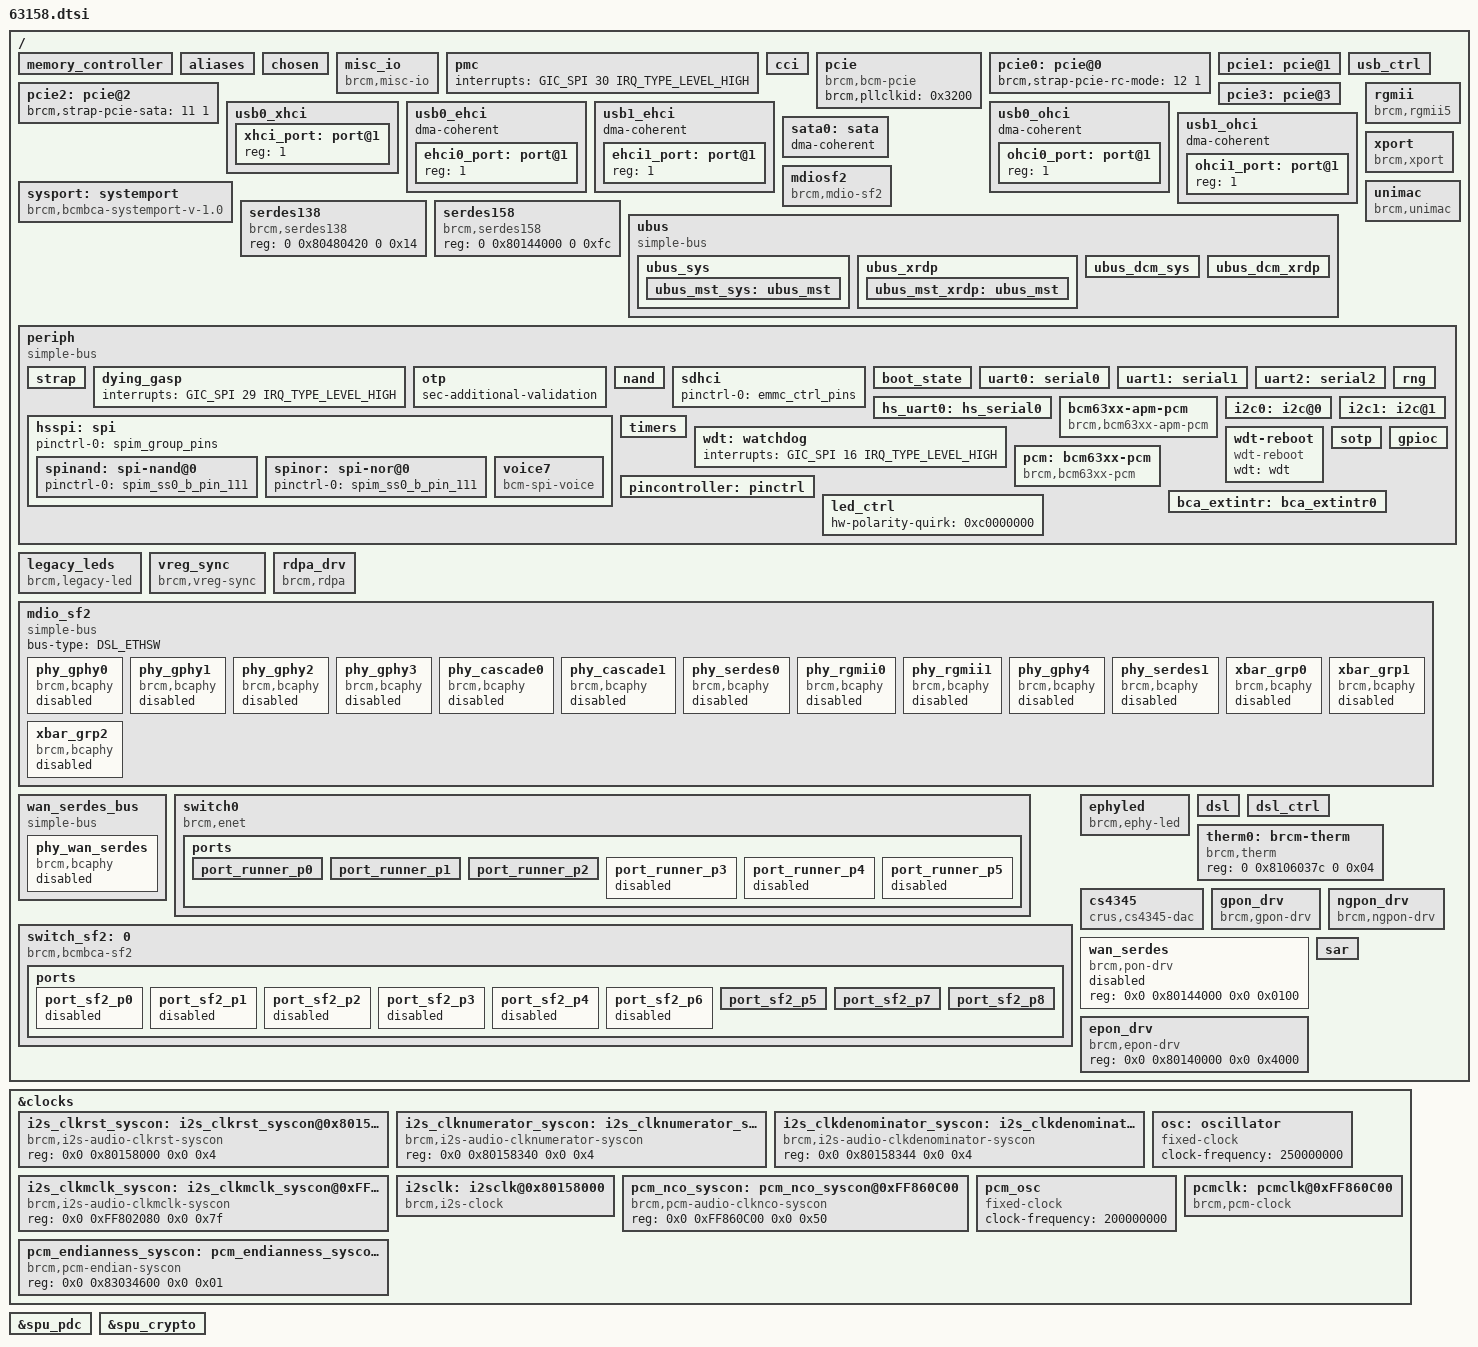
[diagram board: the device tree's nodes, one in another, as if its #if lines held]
/dts-v1/;

#include "linux_autoconf.h"

/* bootstrap reserved memory */
#include "../boot_rsvdmem.dtsi"

/ {
	/* arch */
	#define PMU_CORE0_SPI	9
	#define PMU_CORE1_SPI	10
	#define PMU_CORE2_SPI	11
	#define PMU_CORE3_SPI	12
	#include "../ip/bcm_b53_quad.dtsi"

	/* clocks */
	#define PERIPH_CLK		200000000
	#define HS_SPI_PLL_CLK	400000000
	#include "../ip/bcm_clocks.dtsi"

	/* broadcom memory reservations */
	#include "../bcm_rsvdmem.dtsi"

	/* memc */
	memory_controller {
		#define MEMC_REG_NAMES	"memc-int-clear-reg",	\
					"memc-int-mask-clear-reg",\
					"phyctl_idle_pad_ctl",	\
					"phyctl_idle_pad_en0",	\
					"phyctl_idle_pad_en1",	\
					"auto_self_refresh",	\
					"glb_gcfg"

		#define MEMC_REG	<0 0x80180E08 0 4>,	\
					<0 0x80180E14 0 4>,	\
					<0 0x801a0034 0 4>,	\
					<0 0x801a0038 0 4>,	\
					<0 0x801a003c 0 4>,	\
					<0 0x8018025c 0 4>,	\
					<0 0x80180004 0 4>

		#define MEMC_CPU_INT_LINE		18

		#include "../ip/memc.dtsi"
	};

	aliases {
		serial0 = &uart0;
		serial1 = &uart1;
		serial2 = &uart2;
		spi1 = &hsspi; /* 0 = legacy, 1 = high speed */
		spinand0 = &spinand;
		nand0 = &nand;
		spinor0 = &spinor;
		hs_serial0 = &hs_uart0;
	};

	chosen: chosen {
		stdout-path = "serial0:115200n8";
		/* increase coherent_pool size */
		bootargs = "coherent_pool=4M cpuidle_sysfs_switch pci=pcie_bus_safe console=ttyAMA0,115200 earlyprintk  rootwait rng_core.default_quality=1024";
	};

	misc_io {
		compatible = "brcm,misc-io";
		misc-periph-chip-id-rev = <0x0 0xff800000 0x0 0x4>;
		misc-periph-chip-id-mask = <0xfffff000>;
		misc-periph-chip-id-shift = <12>;
		misc-periph-chip-rev-mask = <0xfff>;
	};

	/* PMC */
	pmc: pmc {
		#define PMC_REG_OFFSET              0x0 0x80201000
		#define PMC_REG_SIZE                0x0 0x3800
		#define PROCMON_REG_OFFSET          0x0 0x80280000
		#define PROCMON_REG_SIZE            0x0 0x184
		#include "../ip/bcm_pmc_1_x.dtsi"
		interrupt-names = "pmc-irq";
		interrupts = <GIC_SPI 30 IRQ_TYPE_LEVEL_HIGH>;
	};

	cci: cci {
		#define CCI_OFFSET					0x0 0x81100000 
		#define CCI_SIZE					0x0 0x8000
		#define SLAVEINTF_CPU_NUM			1
		#include "../ip/bcm_arm_cci500.dtsi"
	};
	
#if defined(CONFIG_BCM_PCIE_HCD) || defined(CONFIG_BCM_PCIE_HCD_MODULE)
	/* pcie common */
	pcie: pcie {
		compatible = "brcm,bcm-pcie";
		device_type = "cpci";
#if (CONFIG_BRCM_CHIP_REV!=0x63158A0)
		/* port 0,1 share same clock */
		brcm,pllclkid = <0x3200>;
#else
		brcm,pllclkid = <0x3210>;
#endif
	};

	/* pcie core 0 */
	pcie0: pcie@0 {
		#define PCIE_ID				0
		#define PCIE_SPI			60
		#define PCIE_ADDR			0x80040000
		#define PCIE_SIZE			0x0000A000
		#define PCIE_RANGE_ADDR		0xC0000000
		#define PCIE_RANGE_SIZE		0x10000000
		#include "../ip/bcm_pcie_core.dtsi" 
		brcm,strap-pcie-rc-mode=<12 1>; 
	};

	/* pcie core 1 */
	pcie1: pcie@1 {
		#define PCIE_ID				1
		#define PCIE_SPI			61
		#define PCIE_ADDR			0x80050000
		#define PCIE_SIZE			0x0000A000
		#define PCIE_RANGE_ADDR		0xD0000000
		#define PCIE_RANGE_SIZE		0x10000000
		#include "../ip/bcm_pcie_core.dtsi"
	};

	/* pcie core 2 */
	pcie2: pcie@2 {
		#define PCIE_ID				2
		#define PCIE_SPI			62
		#define PCIE_ADDR			0x80060000
		#define PCIE_SIZE			0x0000A000
		#define PCIE_RANGE_ADDR		0xE0000000
		#define PCIE_RANGE_SIZE		0x10000000
		#include "../ip/bcm_pcie_core.dtsi"
		brcm,strap-pcie-sata=<11 1>;
	};

	/* pcie core 3 */
	pcie3: pcie@3 {
		#define PCIE_ID				3
		#define PCIE_SPI			63
		#define PCIE_ADDR			0x80070000
		#define PCIE_SIZE			0x0000B000
		#define PCIE_RANGE_ADDR		0xB0000000
		#define PCIE_RANGE_SIZE		0x10000000
		#include "../ip/bcm_pcie_core.dtsi"
	};
#endif /* defined(CONFIG_BCM_PCIE_HCD) || defined(CONFIG_BCM_PCIE_HCD_MODULE) */

#if (defined(CONFIG_BCM_PDC) || defined(CONFIG_BCM_PDC_MODULE)) && \
    (defined(CONFIG_BCM_SPU) || defined(CONFIG_BCM_SPU_MODULE))
	/* spu */
	#define SPU_DMA_ADDR			0x00000000 0x8001c000
	#define SPU_DMA_SIZE			0x00000000 0x448
	#define SPU_DMA_NUM_CHAN		4
	#define SPU_DMA_NUM_AE			1
	#define SPU_CRYPTO_ADDR			0x00000000 0x8001d000
	#define SPU_CRYPTO_SIZE			0x00000000 0x64
	#define SPU_GMAC_SPI			75
	#include "../ip/bcm_spu.dtsi"
#endif

	/* usb */
	usb_ctrl: usb_ctrl {
		#define USB_CTRL_ADDR		0x0 0x8000c200
		#define USB_CTRL_SIZE 		0x0 0x100
		#include "../ip/bcm_usb_ctrl.dtsi"
	};

	usb0_xhci: usb0_xhci {
		#define USB_ADDR 		0x0 0x8000d000
		#define USB_SIZE		0x0 0x1000
		#define USB_IRQ			123
		#include "../ip/bcm_usb_xhci.dtsi"

		xhci_port: port@1{
			reg = <1>;
			#trigger-source-cells = <0>;
		};
	};

	usb0_ehci: usb0_ehci {
		#define USB_ADDR		0x0 0x8000c300
		#define USB_SIZE		0x0 0x100
		#define USB_IRQ			125
		#include "../ip/bcm_usb_ehci.dtsi"

  		dma-coherent;

 		ehci0_port: port@1{
			reg = <1>;
			#trigger-source-cells = <0>;
		};
	};

	usb1_ehci: usb1_ehci {
		#define USB_ADDR		0x0 0x8000c500
		#define USB_SIZE		0x0 0x100
		#define USB_IRQ			122
		#include "../ip/bcm_usb_ehci.dtsi"

  		dma-coherent;

		ehci1_port: port@1{
			reg = <1>;
			#trigger-source-cells = <0>;
		};
	};

	usb0_ohci: usb0_ohci {
		#define USB_ADDR		0x0 0x8000c400
		#define USB_SIZE		0x0 0x100
		#define USB_IRQ			124
		#include "../ip/bcm_usb_ohci.dtsi"

  		dma-coherent;

 		ohci0_port: port@1{
			reg = <1>;
			#trigger-source-cells = <0>;
		};
	};

	usb1_ohci: usb1_ohci {
		#define USB_ADDR		0x0 0x8000c600
		#define USB_SIZE		0x0 0x100
		#define USB_IRQ			121
		#include "../ip/bcm_usb_ohci.dtsi"

  		dma-coherent;

 		ohci1_port: port@1{
			reg = <1>;
			#trigger-source-cells = <0>;
		};
	};

	sata0: sata {
		#define AHCI_ADDR		0x0 0x8000a000
		#define AHCI_SIZE		0x0 0x2c
		#define SATA_CTRL_ADDR	0x0 0x80008000
		#define SATA_CTRL_SIZE	0x0 0x2000
		#define AHCI_SS_ADDR	0x0 0x8000a100
		#define AHCI_SS_SIZE	0x0 0x80
		#define AHCI_IRQ		45
		#include "../ip/bcm_sata.dtsi"
#if defined(CONFIG_BCM_GLB_COHERENCY)		
		dma-coherent;
#endif
	};

	sysport: systemport {
		compatible = "brcm,bcmbca-systemport-v-1.0";
		qphy-avaiable=<0x01>;
		sphy-available=<0x01>;
		reg-names = "systemport-rbuf-base", "systemport-rdma-base",
				"systemport-tdma-base",
				"systemport-umac-base",
				"systemport-topctrl-base";
		reg =	<0x0 0x80490400 0x0 0x14>,
			<0x0 0x80492000 0x0 0x1060>,
			<0x0 0x80494000 0x0 0x650>,
			<0x0 0x80490800 0x0 0x650>,
			<0x0 0x80490000 0x0 0x10>;
		ethsw = <&switch_sf2>;
	};

	mdiosf2 {
		compatible = "brcm,mdio-sf2";
		reg = <0x0 0x804805c0 0x0 0x10>,
		      <0x0 0x80480000 0x0 0x4>;
	};

	rgmii: rgmii {
		compatible = "brcm,rgmii5";
		reg = <0x0 0x80480164 0x0 12>, <0x0 0xff85a000 0x0 4>, /* rgmii0 P12 crossbar external EP3 */
		      <0x0 0x80480158 0x0 12>, <0x0 0xff85a004 0x0 4>, /* rgmii1 P11 crossbar external EP2 */
		      <0x0 0x80480170 0x0 12>, <0x0 0xff85a008 0x0 4>; /* rgmii2 P13/SF2.P3 */
	};

	xport {
		compatible = "brcm,xport";
		reg = <0x0 0x80138000 0x0 0x331c>,  /* XPORT base */
		      <0x0 0x80147800 0x0 0x0800>;  /* XLIF base */
	};

	unimac {
		compatible = "brcm,unimac";
		reg = <0x0 0x82da0000 0x0 0x3000>,
			  <0x0 0x82da8000 0x0 0xc00>,
			  <0x0 0x82daa000 0x0 0xc00>;
		conf_offset = <0x1000>;
		mib_offset = <0x400>;
		top_offset = <0x400>;
	};

	serdes138 {
		compatible = "brcm,serdes138";
		reg = <0 0x80480420 0 0x14>;   /* SINGLE_SERDES */
	};

	serdes158 {
		compatible = "brcm,serdes158";
		reg = <0 0x80144000 0 0xfc>;   /* WAN_TOP */
	};

	/* UBUS */
	ubus: ubus {
		compatible = "simple-bus";
		#address-cells = <2>;
		#size-cells = <2>;
		ranges;

		ubus_sys: ubus_sys {
			#address-cells = <2>;
			#size-cells = <2>;
			#define UBUS_SYSTOP_OFFSET         0x0 0x83000000
			#define UBUS_SYSTOP_SIZE           0x0 0x80
			#define UBUS_REGISTRATION_OFFSET   0x0 0x83000200
			#define UBUS_REGISTRATION_SIZE     0x0 0x80
			#define UBUS_COHERENCY_PORT_OFFSET 0x0 0x810A0400
			#define UBUS_COHERENCY_PORT_SIZE   0x0 0x400
			#define UBUS_MODULE_XRDP           0x0
			#include "../ip/bcm_ubus4.dtsi"
			ubus_mst_sys: ubus_mst {
				reg-names = "BIU", "PER", "USB", "SPU",
					"DSL", "PERDMA", "PCIE0", "PCIE2",
					"PCIE3", "DSLCPU", "PMC", "SWH";
				reg = <0x0 0x83020000 0x0 0x1000>,
					<0x0 0x83034000 0x0 0x1000>,
					<0x0 0x83074000 0x0 0x1000>,
					<0x0 0x83050000 0x0 0x1000>,
					<0x0 0x8305C000 0x0 0x1000>,
					<0x0 0x8303C000 0x0 0x1000>,
					<0x0 0x8300C000 0x0 0x1000>,
					<0x0 0x83064000 0x0 0x1000>,
					<0x0 0x8306C000 0x0 0x1000>,
					<0x0 0x8301C000 0x0 0x1000>,
					<0x0 0x8302C000 0x0 0x1000>,
					<0x0 0x83048000 0x0 0x1000>;
			};
		};

		ubus_xrdp: ubus_xrdp {
			#address-cells = <2>;
			#size-cells = <2>;
			#define UBUS_SYSTOP_OFFSET        0x0 0x83400000
			#define UBUS_SYSTOP_SIZE          0x0 0x80
			#define UBUS_REGISTRATION_OFFSET  0x0 0x83400200
			#define UBUS_REGISTRATION_SIZE    0x0 0x80
			#define UBUS_MODULE_XRDP          0x1
			#include "../ip/bcm_ubus4.dtsi"
			ubus_mst_xrdp: ubus_mst {
				reg-names = "QM", "DQM", "DMA0", "NATC",
					"RQ0";
				reg = <0x0 0x834C4000 0x0 0x1000>,
					<0x0 0x834BC000 0x0 0x1000>,
					<0x0 0x8347C000 0x0 0x1000>,
					<0x0 0x834B8000 0x0 0x1000>,
					<0x0 0x83498000 0x0 0x1000>;
			};
		};

		ubus_dcm_sys: ubus_dcm_sys {
			#define UBUS_DCM_CLK_OFFSET  0x0 0x83000080
			#define UBUS_DCM_CLK_SIZE    0x0 0x80
			#define UBUS_MODULE_XRDP     0x0
			#include "../ip/bcm_ubus4_dcm.dtsi"
		};
		ubus_dcm_xrdp: ubus_dcm_xrdp {
			#define UBUS_DCM_CLK_OFFSET  0x0 0x83400080
			#define UBUS_DCM_CLK_SIZE    0x0 0x80
			#define UBUS_MODULE_XRDP     0x1
			#include "../ip/bcm_ubus4_dcm.dtsi"
		};
	};

	periph {
		compatible = "simple-bus";
		#address-cells = <2>;
		#size-cells = <2>;
		ranges = <0x0 0x0 0x0 0xff800000 0x0 0x62000>;

		strap: strap {
			#define STRAP_REG_OFFSET            0x0 0x2600
			#define STRAP_REG_SIZE              0x0 0x4
			#include "../ip/bcm_strap.dtsi"
			boot-select-0=<0 1>;
			boot-select-1=<1 1>;
			boot-select-2=<2 1>;
			boot-select-3=<3 1>;
			boot-select-4=<4 1>;
			boot-select-5=<5 1>;
			bootrom-boot=<7 0>;
			sata-strap-enable-bit=<11 0>;
		};

		dying_gasp: dying_gasp {
			#define DG_IRQ_MASK_REG_OFFSET	0x0 0x5A024
			#define DG_IRQ_MASK_REG_SIZE	0x0 0x4
			#define DG_UART_DR_OFFSET	0x0 0x12000
			#define DG_UART_DR_SIZE		0x0 0x4
			#include "../ip/bcm_dgasp_pmc.dtsi"
			interrupts = <GIC_SPI 29 IRQ_TYPE_LEVEL_HIGH>;
		};

		otp: otp {
			#define OTP_REG_OFFSET            0x0 0x2800 
			#define OTP_REG_SIZE              0x0 0x54
			#include "../ip/bcm_otp.dtsi"
			sec-additional-validation;
		};

		/* NAND controller */
		nand: nand {
			pinctrl-0 = <&nand_data_pins &nand_ctrl_pins &nand_ce_b_pin_48>;
			pinctrl-names = "default";
			#define NAND_CTRL_OFFSET		0x0 0x1800
			#define NAND_CTRL_SIZE			0x0 0x400
			#define NAND_INTR_OFFSET		0x0 0x2000
			#define NAND_INTR_SIZE			0x0 0x10
			#define NAND_CACHE_OFFSET		0x0 0x1C00
			#define NAND_CACHE_SIZE			0x0 0x200
			#include "../ip/bcm_nand7_1.dtsi"
		};

	   	/* EMMC */
		sdhci: sdhci {
			pinctrl-0 = <&emmc_ctrl_pins>;
			pinctrl-names="default";	
#if (CONFIG_BRCM_CHIP_REV!=0x63158A0)
			#define SDHCI_OFFSET			0x00000000 0x10000
			#define SDHCI_SIZE			0x00000000 0x100
			#define SDHCI_TOPCFG_OFFSET		0x00000000 0x10100
			#define SDHCI_TOPCFG_SIZE		0x00000000 0x100
			#define SDHCI_BOOT_OFFSET		0x00000000 0x10200
			#define SDHCI_BOOT_SIZE			0x00000000 0x40
			#define SDHCI_AHBSS_CTRL_OFFSET		0x00000000 0x10300
			#define SDHCI_AHBSS_CTRL_SIZE		0x00000000 0x100
#else
			#define SDHCI_OFFSET			0x00000000 0x58000
			#define SDHCI_SIZE			0x00000000 0x100
			#define SDHCI_TOPCFG_OFFSET		0x00000000 0x58100
			#define SDHCI_TOPCFG_SIZE		0x00000000 0x100
			#define SDHCI_BOOT_OFFSET		0x00000000 0x58200
			#define SDHCI_BOOT_SIZE			0x00000000 0x40
			#define SDHCI_AHBSS_CTRL_OFFSET		0x00000000 0x58300
			#define SDHCI_AHBSS_CTRL_SIZE		0x00000000 0x100
#endif				
			#define SDIO_EMMC_SPI			95
			#include "../ip/bcm_sdhci.dtsi"
		};
	
		/* boot state */
		boot_state: boot_state {
			#define RESET_REASON_OFFSET  0x0 0x2628
			#define RESET_REASON_SIZE    0x0 0x4
			#define RESET_STATUS_OFFSET  0x0 0x5a03c
			#define RESET_STATUS_SIZE    0x0 0x4
			#include "../ip/bcm_boot_state_v2.dtsi"
		};

		/* UART 1*/
		uart0: serial0 {
#if (CONFIG_BRCM_CHIP_REV!=0x63158A0)
			#define UART_OFFSET			0x0 0x12000
			#define UART_SIZE			0x0 0x1000
			#define UART_SPI			32
			#define UART_CLK_LABEL			refclk50mhz
			#define UART_CLK			50000000
			#include "../ip/bcm_arm_uart.dtsi"
#else
			#define UART_OFFSET			0x0 0x640
			#define UART_SIZE			0x0 0x18
			#define UART_SPI 			32
			#include "../ip/bcm_uart.dtsi"
#endif
		};

#if (CONFIG_BRCM_CHIP_REV!=0x63158A0)
		uart1: serial1 {
			#define UART_OFFSET			0x0 0x13000
			#define UART_SIZE			0x0 0x1000
			#define UART_SPI			33
			#define UART_CLK_LABEL			refclk50mhz
			#define UART_CLK			50000000
			#include "../ip/bcm_arm_uart.dtsi"
		};

		uart2: serial2 {
			#define UART_OFFSET			0x0 0x14000
			#define UART_SIZE			0x0 0x1000
			#define UART_SPI			35
			#define UART_CLK_LABEL			refclk50mhz
			#define UART_CLK			50000000
			#include "../ip/bcm_arm_uart.dtsi"
		};
#endif

		hs_uart0: hs_serial0 {
#if (CONFIG_BRCM_CHIP_REV!=0x63158A0)
			#define UART_OFFSET			0x0 0x10400
			#define UART_SIZE			0x0 0x1E0
#else			
			#define UART_OFFSET			0x0 0x58400
			#define UART_SIZE			0x0 0x1E0
#endif			
			#define UART_SPI 			34
			#include "../ip/bcm_hs_uart.dtsi"
		};

		/* HS SPI */
		hsspi: spi {
			pinctrl-0 = <&spim_group_pins>;
			pinctrl-names = "default";
			#define HS_SPI_OFFSET			0x0 0x1000
			#define HS_SPI_SIZE			0x0 0x600
			#define HS_SPI_MAX_FREQ			50000000
			/* #define HS_SPIM_SPI			37 */
			#include "../ip/bcm_hsspi.dtsi"
			spinand: spi-nand@0 {
				pinctrl-0 = <&spim_ss0_b_pin_111>;
				pinctrl-names = "default";
				#define SPINAND_MAX_FREQ	50000000
				#include "../ip/bcm_spinand.dtsi"
			};
			spinor: spi-nor@0 {
				pinctrl-0 = <&spim_ss0_b_pin_111>;
				pinctrl-names = "default";
				#define SPINOR_MAX_FREQ	50000000
				#include "../ip/bcm_spinor.dtsi"
			};
			voice7 {
				pinctrl-0 = <&pcm_sdin_pin_42 &pcm_sdout_pin_43 &pcm_clk_pin_44 &pcm_fs_pin_45>;
				pinctrl-names = "default";
				compatible = "bcm-spi-voice";
				reg = <7>; /* chip select 7 */
				spi-index = <7>;/* ZSI/ISI header position index */
				spi-max-frequency = <1024000>;
			};
		};

		bcm63xx-apm-pcm {
			compatible = "brcm,bcm63xx-apm-pcm";
			reg = <0x0 0x60000 0x0 0x1c60>;
			interrupts = <GIC_SPI 78 IRQ_TYPE_LEVEL_HIGH>;
		};		

		rng: rng {
			#define RNG200_OFFSET			0x0 0x00000b80
			#define RNG200_SIZE			0x0 0x28
			#include "../ip/bcm_rng200.dtsi"
		};

		i2c0: i2c@0 {
			#define I2C_OFFSET			0x0 0x2100
			#define I2C_SIZE			0x0 0x60
			#include "../ip/bcm_i2c_bus.dtsi"
		};

		/* use second i2c bus for pon sfp i2c device */
		i2c1: i2c@1 {
			#define I2C_OFFSET			0x0 0x5a800
			#define I2C_SIZE			0x0 0x60
			#include "../ip/bcm_i2c_bus.dtsi"
		};

		/* periph timers */
		timers: timers {
			#define TIMERS_OFFSET		0x0 0x400
			#define TIMERS__SIZE		0x0 0x48
			#define TIMER0_SPI			64
			#define TIMER1_SPI			65
			#define TIMER2_SPI			66
			#define TIMER3_SPI			67
			#include "../ip/bcm_timer.dtsi"
		};

		/* watchdog */
		wdt: watchdog {
			#define WATCHDOG_OFFSET			0x0 0x480
			#define WATCHDOG_SIZE			0x0 0x10
			#define WATCHDOG_TIMEOUT		80
			#include "../ip/bcm_wdt.dtsi"
			interrupts = <GIC_SPI 16 IRQ_TYPE_LEVEL_HIGH>;
		};

		/* watchdog reboot */
		wdt-reboot {
			compatible = "wdt-reboot";
			wdt = <&wdt>;
		};

		/* sotp */
		sotp {
			#define SOTP_OFFSET			0x0 0xc00
			#define SOTP_SIZE			0x0 0x84
			#include "../ip/bcm_sotp.dtsi"
		};
	
		pcm: bcm63xx-pcm {
			compatible = "brcm,bcm63xx-pcm";
			reg = <0x0 0x60C00 0x0 0x1060>;
			interrupts = <GIC_SPI 78 IRQ_TYPE_LEVEL_HIGH>,<GIC_SPI 79 IRQ_TYPE_LEVEL_HIGH>;
			clocks = <&pcmclk>, <&pcm_osc>;
			clock-names = "pcmclk","pcmosc"; 
		};		

		/* pinctrl */
		pincontroller: pinctrl {
			#define PINCTRL_OFFSET       0x0 0x554
			#define PINCTRL_SIZE         0x0 0xc
			#define PINCTRL_NUM_PINS     126
			#define PINCTRL_NUM_FUNC     8
			#define PINCTRL_GPIO_FUNC    5
			#include "../ip/bcm_bca_pinctrl.dtsi"
			#include "63158_pinctrl.dtsi"
		};
		/* gpio */
		gpioc: gpioc {
			#define GPIO_DIR_OFFSET      0x0 0x500
			#define GPIO_DIR_SIZE        0x0 0x20
			#define GPIO_DATA_OFFSET     0x0 0x520
			#define GPIO_DATA_SIZE       0x0 0x20
			#define NUM_OF_GPIOS         126
			#include "../ip/bcm_bca_gpio.dtsi"
		};

		/* external interrups */
		bca_extintr: bca_extintr0 {
			#define EXTINTR_OFFSET       0x0 0x4
			#define EXTINTR_SIZE         0x0 0x48
			#define MAX_EXT_INTR         8
			#include "../ip/bcm_bca_extintr.dtsi"
			external_interrupts = <176 177 178 179 180 181 182 183>;
		};

		/* Led Controller */
		led_ctrl: led_ctrl {
			#define LED_GLBL_CTRL_OFFSET     0 0x800
			#define LED_GLBL_CTRL_SIZE       0 0x4 
			#define LED_HW_EN_OFFSET         0 0x808
			#define LED_HW_EN_SIZE           0 0x4
			#define LED_SER_SHIFT_OFFSET     0 0x80c
			#define LED_SER_SHIFT_SIZE       0 0x4
			#define LED_FLASH_RATE_OFFSET    0 0x810
			#define LED_FLASH_RATE_SIZE      0 0x10
			#define LED_BRIGHTNESS_OFFSET    0 0x820
			#define LED_BRIGHTNESS_SIZE      0 0x10
			#define LED_POWER_LED_CFG_OFFSET 0 0x830
			#define LED_POWER_LED_CFG_SIZE   0 0x4
			#define LED_POWER_LUT_OFFSET     0 0x834
			#define LED_POWER_LUT_SIZE       0 0x80
			#define LED_HW_POLARITY_OFFSET   0 0x8b4
			#define LED_HW_POLARITY_SIZE     0 0x4
			#define LED_SW_DATA_OFFSET       0 0x8b8
			#define LED_SW_DATA_SIZE         0 0x4
			#define LED_SW_POLARITY_OFFSET   0 0x8bc
			#define LED_SW_POLARITY_SIZE     0 0x4
			#define LED_PAR_POLARITY_OFFSET  0 0x8c0
			#define LED_PAR_POLARITY_SIZE    0 0x4
			#define LED_SER_POLARITY_OFFSET  0 0x8c4
			#define LED_SER_POLARITY_SIZE    0 0x4
			#define LED_MASK_OFFSET          0 0x804 /*????*/
			#define LED_MASK_SIZE            0 0x4
			#define MAX_SUPPORTED_LEDS       32

			status = "okay";
			hw-polarity-quirk = <0xc0000000>;
			#include "../ip/bcm_led_ctrl.dtsi"
			#include "63158_leds.dtsi"
		};
	};

	legacy_leds: legacy_leds {
		compatible = "brcm,legacy-led";
	};

	vreg_sync: vreg_sync {
		compatible = "brcm,vreg-sync";
	};

	/* xrdp,wan_bbh,xlif */
	rdpa_drv {
		compatible = "brcm,rdpa";
		reg = <0x0 0x82000000 0x0 0xE51000>, 
			<0x0 0x80170000 0x0 0x9000>, 
			<0x0 0x80147800 0x0 0x800>;
                interrupts = <GIC_SPI 106 IRQ_TYPE_LEVEL_HIGH>, /* INTERRUPT_XRDP_FPM */
                             <GIC_SPI 128 IRQ_TYPE_LEVEL_HIGH>, /* INTERRUPT_XRDP_QUEUE_0 */
                             <GIC_SPI 129 IRQ_TYPE_LEVEL_HIGH>, /* INTERRUPT_XRDP_QUEUE_1 */
                             <GIC_SPI 130 IRQ_TYPE_LEVEL_HIGH>, /* INTERRUPT_XRDP_QUEUE_2 */
                             <GIC_SPI 131 IRQ_TYPE_LEVEL_HIGH>, /* INTERRUPT_XRDP_QUEUE_3 */
                             <GIC_SPI 132 IRQ_TYPE_LEVEL_HIGH>, /* INTERRUPT_XRDP_QUEUE_4 */
                             <GIC_SPI 133 IRQ_TYPE_LEVEL_HIGH>, /* INTERRUPT_XRDP_QUEUE_5 */
                             <GIC_SPI 134 IRQ_TYPE_LEVEL_HIGH>, /* INTERRUPT_XRDP_QUEUE_6 */
                             <GIC_SPI 135 IRQ_TYPE_LEVEL_HIGH>, /* INTERRUPT_XRDP_QUEUE_7 */
                             <GIC_SPI 136 IRQ_TYPE_LEVEL_HIGH>, /* INTERRUPT_XRDP_QUEUE_8 */
                             <GIC_SPI 137 IRQ_TYPE_LEVEL_HIGH>, /* INTERRUPT_XRDP_QUEUE_9 */
                             <GIC_SPI 138 IRQ_TYPE_LEVEL_HIGH>, /* INTERRUPT_XRDP_QUEUE_10 */
                             <GIC_SPI 139 IRQ_TYPE_LEVEL_HIGH>, /* INTERRUPT_XRDP_QUEUE_11 */
                             <GIC_SPI 140 IRQ_TYPE_LEVEL_HIGH>, /* INTERRUPT_XRDP_QUEUE_12 */
                             <GIC_SPI 141 IRQ_TYPE_LEVEL_HIGH>, /* INTERRUPT_XRDP_QUEUE_13 */
                             <GIC_SPI 142 IRQ_TYPE_LEVEL_HIGH>, /* INTERRUPT_XRDP_QUEUE_14 */
                             <GIC_SPI 143 IRQ_TYPE_LEVEL_HIGH>, /* INTERRUPT_XRDP_QUEUE_15 */
                             <GIC_SPI 144 IRQ_TYPE_LEVEL_HIGH>, /* INTERRUPT_XRDP_QUEUE_16 */
                             <GIC_SPI 145 IRQ_TYPE_LEVEL_HIGH>, /* INTERRUPT_XRDP_QUEUE_17 */
                             <GIC_SPI 146 IRQ_TYPE_LEVEL_HIGH>, /* INTERRUPT_XRDP_QUEUE_18 */
                             <GIC_SPI 147 IRQ_TYPE_LEVEL_HIGH>, /* INTERRUPT_XRDP_QUEUE_19 */
                             <GIC_SPI 148 IRQ_TYPE_LEVEL_HIGH>, /* INTERRUPT_XRDP_QUEUE_20 */
                             <GIC_SPI 149 IRQ_TYPE_LEVEL_HIGH>, /* INTERRUPT_XRDP_QUEUE_21 */
                             <GIC_SPI 150 IRQ_TYPE_LEVEL_HIGH>, /* INTERRUPT_XRDP_QUEUE_22 */
                             <GIC_SPI 151 IRQ_TYPE_LEVEL_HIGH>, /* INTERRUPT_XRDP_QUEUE_23 */
                             <GIC_SPI 152 IRQ_TYPE_LEVEL_HIGH>, /* INTERRUPT_XRDP_QUEUE_24 */
                             <GIC_SPI 153 IRQ_TYPE_LEVEL_HIGH>, /* INTERRUPT_XRDP_QUEUE_25 */
                             <GIC_SPI 154 IRQ_TYPE_LEVEL_HIGH>, /* INTERRUPT_XRDP_QUEUE_26 */
                             <GIC_SPI 155 IRQ_TYPE_LEVEL_HIGH>, /* INTERRUPT_XRDP_QUEUE_27 */
                             <GIC_SPI 156 IRQ_TYPE_LEVEL_HIGH>, /* INTERRUPT_XRDP_QUEUE_28 */
                             <GIC_SPI 157 IRQ_TYPE_LEVEL_HIGH>, /* INTERRUPT_XRDP_QUEUE_29 */
                             <GIC_SPI 158 IRQ_TYPE_LEVEL_HIGH>, /* INTERRUPT_XRDP_QUEUE_30 */
                             <GIC_SPI 159 IRQ_TYPE_LEVEL_HIGH>, /* INTERRUPT_XRDP_QUEUE_31 */
		             <GIC_SPI 111 IRQ_TYPE_LEVEL_HIGH>, /* INTERRUPT_RUNNER_0 */
		             <GIC_SPI 112 IRQ_TYPE_LEVEL_HIGH>, /* INTERRUPT_RUNNER_1 */
		             <GIC_SPI 113 IRQ_TYPE_LEVEL_HIGH>, /* INTERRUPT_RUNNER_2 */
		             <GIC_SPI 114 IRQ_TYPE_LEVEL_HIGH>, /* INTERRUPT_RUNNER_3 */
		             <GIC_SPI 115 IRQ_TYPE_LEVEL_HIGH>, /* INTERRUPT_RUNNER_4 */
		             <GIC_SPI 116 IRQ_TYPE_LEVEL_HIGH>; /* INTERRUPT_RUNNER_5 */
        interrupt-names = "fpm", "queue0", "queue1", "queue2", "queue3", "queue4", "queue5",
                          "queue6", "queue7", "queue8", "queue9", "queue10", "queue11", 
                          "queue12", "queue13", "queue14", "queue15", "queue16", "queue17",
                          "queue18", "queue19", "queue20", "queue21", "queue22", "queue23",
                          "queue24", "queue25", "queue26", "queue27", "queue28", "queue29",
                          "queue30", "queue31",
                          "runner0", "runner1", "runner2", "runner3", "runner4", "runner5";
	};

	mdio_sf2: mdio_sf2 {
		compatible = "simple-bus";
		bus-type = "DSL_ETHSW";
		#address-cells = <1>;
		#size-cells = <0>;

		/* Port PHY mapping:
            port_runner_p0  <-->  port_sf2_p8 -###- port_sf2_p0 <------------------> phy_gphy0
            port_runner_p1  <-->  port_sf2_p5 -# #- port_sf2_p1 <------------------> phy_gphy1
            port_runner_p2  <-->  port_sf2_p7 -# #- port_sf2_p2 <------------------> phy_gphy2
                                               # #- port_sf2_p3 <------------------> phy_gphy3
                                               # #- port_sf2_p4 <--> xbar_grp0 -+-+- phy_serdes1 (2.5G)
                                               ###- port_sf2_p6 <--> xbar_grp1 -+ +- phy_gphy4
                                                 port_runner_p5 <--> xbar_grp2 -+ +- phy_rgmii1
                                                                                +-+- phy_rgmii0         
                                              port_runner_p4/P3 <------------------> phy_serdes0 (10G) /PON
		 */
		/* PHYs directly connected to SF2 */
		phy_gphy0:phy_gphy0 {
			compatible = "brcm,bcaphy";
			reg = <0x8>;
			phy-type = "EGPHY";
			status = "disabled";
		};
		phy_gphy1:phy_gphy1 {
			compatible = "brcm,bcaphy";
			reg = <0x9>;
			phy-type = "EGPHY";
			status = "disabled";
		};
		phy_gphy2:phy_gphy2 {
			compatible = "brcm,bcaphy";
			reg = <0xa>;
			phy-type = "EGPHY";
			status = "disabled";
		};
		phy_gphy3:phy_gphy3 {
			compatible = "brcm,bcaphy";
			reg = <0xb>;
			phy-type = "EGPHY";
			status = "disabled";
		};

		/* Cascade PHYs */
		phy_cascade0:phy_cascade0 {
			compatible = "brcm,bcaphy";
			phy-type = "EXT3";
			reg = <31>;
			status = "disabled";
			phy-external;
		};
		phy_cascade1:phy_cascade1 {
			compatible = "brcm,bcaphy";
			phy-type = "EXT3";
			reg = <30>;
			status = "disabled";
			phy-external;
		};
			
		/* PHY directly connected to Runner */
		phy_serdes0:phy_serdes0 {
			compatible = "brcm,bcaphy";
			phy-type = "10GAE";
			reg = <0>;
			phy-mode = "serdes";
			status = "disabled";
		};

		/* PHYs connected to crossbar */
		phy_rgmii0:phy_rgmii0 {
			compatible = "brcm,bcaphy";
			phy-type = "EGPHY";
			reg = <25>;
			xbar-ext-ep = <3>;          /* external endpoint3 */
			phy-mode = "rgmii";
			rgmii-intf = <0>;
			rgmii-1p8v;
			phy-external;
			status = "disabled";

			pinctrl-names = "default"; 
			pinctrl-0 = <&mii_pins>;
		};
		phy_rgmii1:phy_rgmii1 {
			compatible = "brcm,bcaphy";
			phy-type = "EGPHY";
			reg = <24>;
			xbar-ext-ep = <2>;          /* external endpoint2 */
			phy-mode = "rgmii";
			rgmii-intf = <1>;
			rgmii-1p8v;
			phy-external;
			status = "disabled";

			pinctrl-names = "default"; 
			pinctrl-0 = <&rgmii1_pins>;
		};
		phy_gphy4:phy_gphy4 {
			compatible = "brcm,bcaphy";
			reg = <0xc>;
			phy-type = "EGPHY";
			xbar-ext-ep = <1>;          /* external endpoint1 */
			phy-mode = "gmii";
			status = "disabled";
		};
		phy_serdes1:phy_serdes1 {
			compatible = "brcm,bcaphy";
			phy-type = "2.5AE";
			reg = <6>;
			xbar-ext-ep = <0>;          /* external endpoint0 */
			phy-mode = "serdes";
			status = "disabled";
		};

		/* Crossbar groups */
		xbar_grp0:xbar_grp0 {                   /* internal endpoint0 SF2.p4 */
			compatible = "brcm,bcaphy";
			phy-type = "crossbar";
			reg = <0>;
			status = "disabled";
		};
		xbar_grp1:xbar_grp1 {                   /* internal endpoint1 SF2.p6 */
			compatible = "brcm,bcaphy";
			phy-type = "crossbar";
			reg = <1>;
			status = "disabled";
		};
		xbar_grp2:xbar_grp2 {                   /* internal endpoint2 runner.p5 */
			compatible = "brcm,bcaphy";
			phy-type = "crossbar";
			reg = <2>;
			status = "disabled";
		};
	};

	wan_serdes_bus {
		compatible = "simple-bus";

		#address-cells = <1>;
		#size-cells = <0>;

		phy_wan_serdes: phy_wan_serdes {
			compatible = "brcm,bcaphy";
			phy-type = "PON";
			reg = <0>;
			status = "disabled";
		};
	};

	switch0:switch0 {
		compatible = "brcm,enet";
		label = "bcmsw";
		sw-type = "RUNNER_SW";

		ports {
			#address-cells = <1>;
			#size-cells = <0>;

			port_runner_p0 {
				reg = <0>;
				mac-type = "UNIMAC";
				link = <&switch_sf2>;   /* runner.p0 <--> sf2.p8 */
				phy-mode = "gmii";
				gmii-direct;
				status = "okay";
			};
			port_runner_p1 {
				management; multi-imp;  /* runner.p1 <--> sf2.p5 */
				reg = <1>;
				mac-type = "UNIMAC";
				phy-mode = "gmii";
				gmii-direct;
				shrink-ipg;
				status = "okay";
			};
			port_runner_p2 {
				management; multi-imp;  /* runner.p2 <--> sf2.p7 */
				reg = <2>;
				mac-type = "UNIMAC";
				phy-mode = "gmii";
				gmii-direct;
				shrink-ipg;
				status = "okay";
			};
			port_runner_p3 {
				reg = <3>;
				phy-handle = <&phy_wan_serdes>;
				detect;
				is-wan;
				is-wanconf-mux-pon;
				status = "disabled";
			};
			port_runner_p4 {
				reg = <4>;
				mac-type = "XPORT";
				mac-index = <0>;       /* XPORT_INTF_AE */
				phy-handle = <&phy_serdes0>;
				phy-mode = "serdes";
				cap-wan-only;
				status = "disabled";
			};
			port_runner_p5 {
				reg = <5>;
				mac-type = "XPORT";
				mac-index = <1>;       /* XPORT_INTF_CB */
				phy-handle = <&xbar_grp2>;
				phy-mode = "serdes";
				cap-wan-only;
				status = "disabled";
			};
		};
	};

	switch_sf2:0 {
		unit= <1>;
		sw-type = "SF2_SW";

		compatible = "brcm,bcmbca-sf2", "brcm,swblks";
		phy_base = <0x8>;
		phy_wkard_timeout = <25000>;
		reg-names = "switchcore-base",
					"switchreg-base",
					"switchmdio-base",
					"switchfcb-base",
					"switchacb-base",
					"xbar-ctrl",
					"qphy-ctrl",
					"sphy-ctrl",
					"phy-test-ctrl";

		reg = <0x0 0x80400000 0x0 0x72724>,
			<0x0 0x80480000 0x0 0x458>,
			<0x0 0x804805c0 0x0 0x10>,
			<0 0x80480600 0 0x154>,
			<0 0x80480800 0 0x208>,
			<0 0x804800cc 0 0x04>,
			<0x0 0x8048001c 0x0 0x04>,
			<0x0 0x80480024 0x0 0x04>,
			<0x0 0x80480018 0x0 0x04>;

		ports {
			#address-cells = <1>;
			#size-cells = <0>;
			
			/* ports connect directly */
			port_sf2_p0 {
				phy-handle = <&phy_gphy0>;
				reg = <0>;
				mac-type = "SF2MAC";
				phy-mode = "gmii";
				gmii-direct;
				cap-lan-only;
				status = "disabled";
			};
			port_sf2_p1 {
				phy-handle = <&phy_gphy1>;
				reg = <1>;
				mac-type = "SF2MAC";
				phy-mode = "gmii";
				gmii-direct;
				cap-lan-only;
				status = "disabled";
			};
			port_sf2_p2 {
				phy-handle = <&phy_gphy2>;
				reg = <2>;
				mac-type = "SF2MAC";
				phy-mode = "gmii";
				gmii-direct;
				cap-lan-only;
				status = "disabled";
			};
			port_sf2_p3 {
				phy-handle = <&phy_gphy3>;
				reg = <3>;
				mac-type = "SF2MAC";
				phy-mode = "gmii";
				gmii-direct;
				cap-lan-only;
				status = "disabled";
			};

			/* ports connected to crossbar */
			port_sf2_p4 {
				phy-handle = <&xbar_grp0>;
				reg = <4>;
				mac-type = "SF2MAC";
				phy-mode = "gmii";
				gmii-direct;
				cap-lan-only;
				status = "disabled";
			};
			port_sf2_p6 {
				phy-handle = <&xbar_grp1>;
				reg = <6>;
				mac-type = "SF2MAC";
				phy-mode = "gmii";
				gmii-direct;
				cap-lan-only;
				status = "disabled";
			};

			/* IMP ports */
			port_sf2_p5 {
				management;     /* sf2.p5 <--> runner.p1 */
				reg = <5>;
				mac-type = "SF2MAC";
				shrink-ipg;
				phy-mode = "gmii";
				gmii-direct;
				status = "okay";
			};
			port_sf2_p7 {
				management;     /* sf2.p7 <--> runner.p2 */
				reg = <7>;
				mac-type = "SF2MAC";
				shrink-ipg;
				phy-mode = "gmii";
				gmii-direct;
				status = "okay";
			};
			port_sf2_p8 {
				management;     /* sf2.p8 <--> runner.p0 */
				reg = <8>;
				mac-type = "SF2MAC";
				phy-mode = "gmii";
				gmii-direct;
				status = "okay";
			};
		};
	};

	ephyled {
		compatible = "brcm,ephy-led";
		led_reg_max = <0x9>;
		/* only define the switch and xport led reg that are actually used.*/
		/* sf2 port0, sf2 port1, sf2 port 2, sf2 port3, sf2 port4, sf port6, xport0, xport1, aggr */
		reg-names = "led_reg_0", "led_reg_1", "led_reg_2", "led_reg_3", "led_reg_4",\
			"led_reg_5", "led_reg_6", "led_reg_7", "aggregate_ctrl";
		reg = <0 0x80480040 0 0xc>, <0 0x8048004c 0 0xc>, <0 0x80480058 0 0xc>,\
			<0 0x80480064 0 0xc>, <0 0x80480070 0 0xc>, <0 0x80480088 0 0xc>,\
			<0 0x8013a074 0 0xc>, <0 0x8013a080 0 0xc>, <0 0x804800c4 0 0x4>;
		5g-led-workarround;
	};

	dsl:dsl {
		#define DSL_LINE_0
		#define DSL_LINE_1	
		#include "../ip/bcm_dsl.dtsi"
	};

	dsl_ctrl: dsl_ctrl {
		#define DSL_PHY_OFFSET		0x0 0x80650000
		#define DSL_PHY_SIZE		0x0 0x20000
		#define DSL_LMEM_OFFSET		0x0 0x80800000
		#define DSL_LMEM_SIZE		0x0 0xe0000
		#define DSL_XMEM_OFFSET		0x0 0x809A0000
		#define DSL_XMEM_SIZE		0x0 0x660000
		#define DSL_SPI				40
		#include "../ip/bcm_dsl_ctrl.dtsi"
	};

	therm0: brcm-therm {
		compatible = "brcm,therm";
		reg-names="bac_cpu_therm_temp";
		reg = <0 0x8106037c 0 0x04>;
	};
	
	cs4345 {
		compatible = "crus,cs4345-dac";
	};

        gpon_drv {
            compatible = "brcm,gpon-drv";
            reg = <0x0 0x80148000 0x0 0x9000>;
            interrupts = <GIC_SPI 99  IRQ_TYPE_LEVEL_HIGH>, /* INTERRUPT_WAN_GPON_RX */
                         <GIC_SPI 98  IRQ_TYPE_LEVEL_HIGH>; /* INTERRUPT_WAN_GPON_TX */
            interrupt-names = "gpon_rx", "gpon_tx";
        };
        ngpon_drv {
            compatible = "brcm,ngpon-drv";
            reg = <0x0 0x80160000 0x0 0xd100>;
            interrupts = <GIC_SPI 164  IRQ_TYPE_LEVEL_HIGH>, /* INTERRUPT_WAN_XGRX */
                         <GIC_SPI 160  IRQ_TYPE_LEVEL_HIGH>, /* INTERRUPT_WAN_XGTX_INTR0 */
                         <GIC_SPI 161  IRQ_TYPE_LEVEL_HIGH>, /* INTERRUPT_WAN_XGTX_INTR1 */
                         <GIC_SPI 162  IRQ_TYPE_LEVEL_HIGH>, /* INTERRUPT_WAN_XGTX_INTR2 */
                         <GIC_SPI 163  IRQ_TYPE_LEVEL_HIGH>; /* INTERRUPT_WAN_XGTX_INTR3 */
            interrupt-names = "ngpon_rx", "ngpon_tx0", "ngpon_tx1", "ngpon_tx2", "ngpon_tx3";
        };
        wan_serdes {
            compatible = "brcm,pon-drv";
            status = "disabled";
            reg = <0x0 0x80144000 0x0 0x0100>;
        };
        epon_drv {
            compatible = "brcm,epon-drv";
            reg = <0x0 0x80140000 0x0 0x4000>;
        };

   sar:sar {
      #define SAR_OFFSET   0x0 0x80130000
      #define SAR_SIZE     0x0 0x4000
      #define TXPAF_OFFSET 0x0 0x80657800
      #define TXPAF_SIZE   0x0 0x4
      #define SAR_CLK_FREQ "409000000"
      #include "../ip/bcm_sar.dtsi"
   };
};

&clocks {
	#address-cells = <2>;
	#size-cells = <2>;
	i2s_clkrst_syscon: i2s_clkrst_syscon@0x80158000 {
		compatible = "brcm,i2s-audio-clkrst-syscon", "syscon";
		reg = <0x0 0x80158000 0x0 0x4>;
	};
	i2s_clknumerator_syscon: i2s_clknumerator_syscon@0x80158340 {
		compatible = "brcm,i2s-audio-clknumerator-syscon", "syscon";
		reg = <0x0 0x80158340 0x0 0x4>;
	};
	i2s_clkdenominator_syscon: i2s_clkdenominator_syscon@0x80158344 {
		compatible = "brcm,i2s-audio-clkdenominator-syscon", "syscon";
		reg = <0x0 0x80158344 0x0 0x4>;
	};
	i2s_clkmclk_syscon: i2s_clkmclk_syscon@0xFF802080 {
		compatible = "brcm,i2s-audio-clkmclk-syscon", "syscon";
		reg = <0x0 0xFF802080 0x0 0x7f>;
	};
	osc: oscillator {
		#clock-cells = <0>;
		compatible = "fixed-clock";
#if (CONFIG_BRCM_CHIP_REV==0x63158A0)
		clock-frequency = <250000000>; /* xpon 250MHz output */
#else
		clock-frequency = <200000000>; /* xpon 200MHz output */
#endif
	};
	i2sclk: i2sclk@0x80158000 {
		#clock-cells = <0>;
		compatible = "brcm,i2s-clock";
		clocks = <&osc>;
		clk-reset-syscon       = <&i2s_clkrst_syscon>;
		clk-numerator-syscon   = <&i2s_clknumerator_syscon>;
		clk-denominator-syscon = <&i2s_clkdenominator_syscon>;
		clk-mclk-syscon        = <&i2s_clkmclk_syscon>;
		clock-output-names     = "i2s_clk";		
	};

	pcm_nco_syscon: pcm_nco_syscon@0xFF860C00 {
		compatible = "brcm,pcm-audio-clknco-syscon", "syscon";
		reg = <0x0 0xFF860C00 0x0 0x50>; /* temp setting here. to do: size should be re-cal for only we need.*/
	};
	pcm_osc: pcm_osc {
		#clock-cells = <0>;
		compatible = "fixed-clock";
		clock-frequency = <200000000>; /* 200.00MHz fixed output */
	};

	pcm_endianness_syscon: pcm_endianness_syscon@0x83034600 {
		compatible = "brcm,pcm-endian-syscon", "syscon";
		reg = <0x0 0x83034600 0x0 0x01>;
	};

	pcmclk: pcmclk@0xFF860C00 {
		#clock-cells = <0>;
		compatible = "brcm,pcm-clock";
		clocks = <&pcm_osc>;
		clk-nco-syscon = <&pcm_nco_syscon>;
		pcm-endian-syscon = <&pcm_endianness_syscon>;
		clock-output-names = "pcm_clk";
	};
};

&nand {
	status = "okay";
};
&uart0 {
	status = "okay";
};
&wdt {
	status = "okay";
};
&i2c0 {
	status = "okay";
};
&i2c1 {
	status = "okay";
};
&sdhci {
	status = "okay";
};
&hsspi {
	status = "okay";
};
&spinand {
	status = "okay";
};
&dsl_ctrl {
	status = "okay";
};
#if (defined(CONFIG_BCM_PDC) || defined(CONFIG_BCM_PDC_MODULE)) && \
    (defined(CONFIG_BCM_SPU) || defined(CONFIG_BCM_SPU_MODULE))
&spu_pdc {
	status = "okay";
};
&spu_crypto {
	status = "okay";
};
&sar {
   status = "okay";
};
#endif

